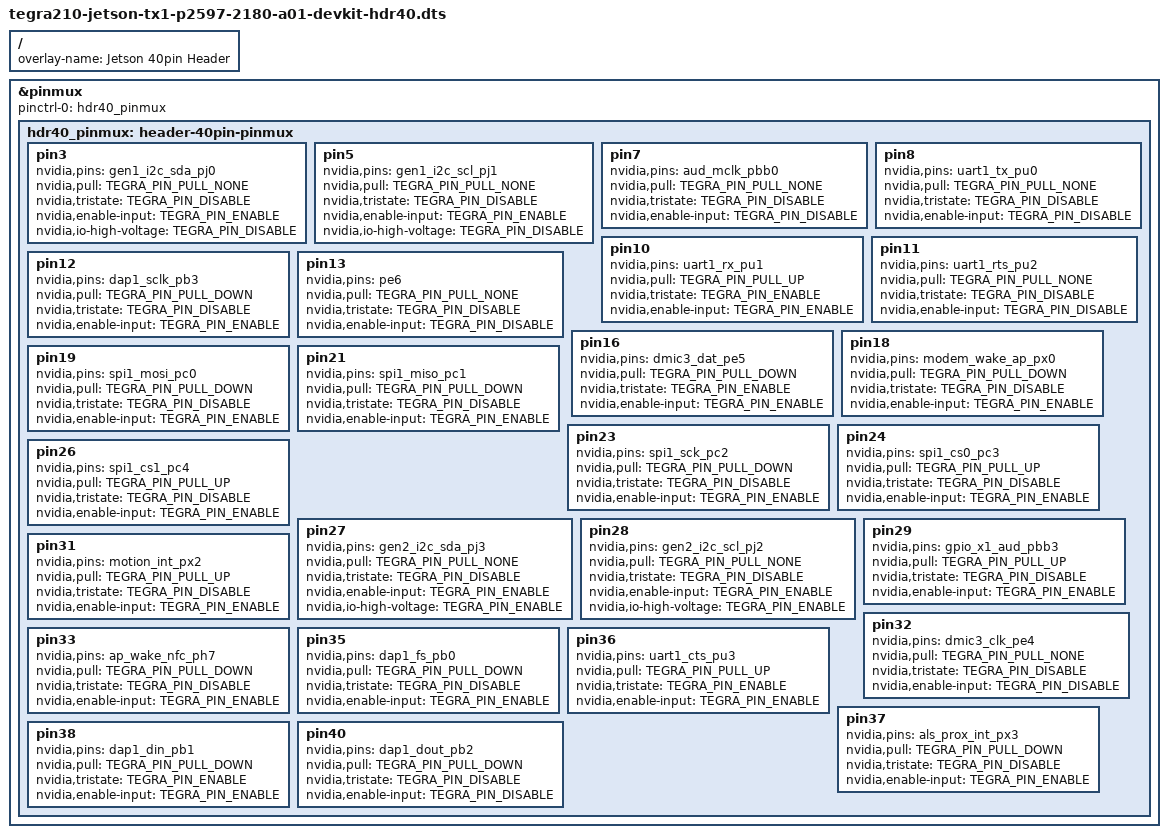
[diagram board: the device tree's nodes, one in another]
// SPDX-License-Identifier: GPL-2.0-only
/*
 * Device-tree overlay for tegra210-jetson-tx1-p2597-2180-a01-devkit
 * 40-pin Expansion Header.
 *
 * Copyright (c) 2019 NVIDIA CORPORATION. All rights reserved.
 *
 */

/dts-v1/;
/plugin/;

#include <dt-bindings/pinctrl/pinctrl-tegra.h>
#include <dt-common/jetson/tegra210-jetson-tx1-p2597-2180-a01-devkit.h>

/ {
	overlay-name = "Jetson 40pin Header";
	compatible = JETSON_COMPATIBLE;

	fragment@0 {
		target = <&pinmux>;
		__overlay__ {
			pinctrl-names = "default";
			pinctrl-0 = <&hdr40_pinmux>;
			hdr40_pinmux: header-40pin-pinmux {
				pin3 {
					nvidia,pins = "gen1_i2c_sda_pj0";
					nvidia,pull = <TEGRA_PIN_PULL_NONE>;
					nvidia,tristate = <TEGRA_PIN_DISABLE>;
					nvidia,enable-input = <TEGRA_PIN_ENABLE>;
					nvidia,io-high-voltage = <TEGRA_PIN_DISABLE>;
				};
				pin5 {
					nvidia,pins = "gen1_i2c_scl_pj1";
					nvidia,pull = <TEGRA_PIN_PULL_NONE>;
					nvidia,tristate = <TEGRA_PIN_DISABLE>;
					nvidia,enable-input = <TEGRA_PIN_ENABLE>;
					nvidia,io-high-voltage = <TEGRA_PIN_DISABLE>;
				};
				pin7 {
					nvidia,pins = "aud_mclk_pbb0";
					nvidia,pull = <TEGRA_PIN_PULL_NONE>;
					nvidia,tristate = <TEGRA_PIN_DISABLE>;
					nvidia,enable-input = <TEGRA_PIN_DISABLE>;
				};
				pin8 {
					nvidia,pins = "uart1_tx_pu0";
					nvidia,pull = <TEGRA_PIN_PULL_NONE>;
					nvidia,tristate = <TEGRA_PIN_DISABLE>;
					nvidia,enable-input = <TEGRA_PIN_DISABLE>;
				};
				pin10 {
					nvidia,pins = "uart1_rx_pu1";
					nvidia,pull = <TEGRA_PIN_PULL_UP>;
					nvidia,tristate = <TEGRA_PIN_ENABLE>;
					nvidia,enable-input = <TEGRA_PIN_ENABLE>;
				};
				pin11 {
					nvidia,pins = "uart1_rts_pu2";
					nvidia,pull = <TEGRA_PIN_PULL_NONE>;
					nvidia,tristate = <TEGRA_PIN_DISABLE>;
					nvidia,enable-input = <TEGRA_PIN_DISABLE>;
				};
				pin12 {
					nvidia,pins = "dap1_sclk_pb3";
					nvidia,pull = <TEGRA_PIN_PULL_DOWN>;
					nvidia,tristate = <TEGRA_PIN_DISABLE>;
					nvidia,enable-input = <TEGRA_PIN_ENABLE>;
				};
				pin13 {
					nvidia,pins = "pe6";
					nvidia,pull = <TEGRA_PIN_PULL_NONE>;
					nvidia,tristate = <TEGRA_PIN_DISABLE>;
					nvidia,enable-input = <TEGRA_PIN_DISABLE>;
				};
				pin16 {
					nvidia,pins = "dmic3_dat_pe5";
					nvidia,pull = <TEGRA_PIN_PULL_DOWN>;
					nvidia,tristate = <TEGRA_PIN_ENABLE>;
					nvidia,enable-input = <TEGRA_PIN_ENABLE>;
				};
				pin18 {
					nvidia,pins = "modem_wake_ap_px0";
					nvidia,pull = <TEGRA_PIN_PULL_DOWN>;
					nvidia,tristate = <TEGRA_PIN_DISABLE>;
					nvidia,enable-input = <TEGRA_PIN_ENABLE>;
				};
				pin19 {
					nvidia,pins = "spi1_mosi_pc0";
					nvidia,pull = <TEGRA_PIN_PULL_DOWN>;
					nvidia,tristate = <TEGRA_PIN_DISABLE>;
					nvidia,enable-input = <TEGRA_PIN_ENABLE>;
				};
				pin21 {
					nvidia,pins = "spi1_miso_pc1";
					nvidia,pull = <TEGRA_PIN_PULL_DOWN>;
					nvidia,tristate = <TEGRA_PIN_DISABLE>;
					nvidia,enable-input = <TEGRA_PIN_ENABLE>;
				};
				pin23 {
					nvidia,pins = "spi1_sck_pc2";
					nvidia,pull = <TEGRA_PIN_PULL_DOWN>;
					nvidia,tristate = <TEGRA_PIN_DISABLE>;
					nvidia,enable-input = <TEGRA_PIN_ENABLE>;
				};
				pin24 {
					nvidia,pins = "spi1_cs0_pc3";
					nvidia,pull = <TEGRA_PIN_PULL_UP>;
					nvidia,tristate = <TEGRA_PIN_DISABLE>;
					nvidia,enable-input = <TEGRA_PIN_ENABLE>;
				};
				pin26 {
					nvidia,pins = "spi1_cs1_pc4";
					nvidia,pull = <TEGRA_PIN_PULL_UP>;
					nvidia,tristate = <TEGRA_PIN_DISABLE>;
					nvidia,enable-input = <TEGRA_PIN_ENABLE>;
				};
				pin27 {
					nvidia,pins = "gen2_i2c_sda_pj3";
					nvidia,pull = <TEGRA_PIN_PULL_NONE>;
					nvidia,tristate = <TEGRA_PIN_DISABLE>;
					nvidia,enable-input = <TEGRA_PIN_ENABLE>;
					nvidia,io-high-voltage = <TEGRA_PIN_ENABLE>;
				};
				pin28 {
					nvidia,pins = "gen2_i2c_scl_pj2";
					nvidia,pull = <TEGRA_PIN_PULL_NONE>;
					nvidia,tristate = <TEGRA_PIN_DISABLE>;
					nvidia,enable-input = <TEGRA_PIN_ENABLE>;
					nvidia,io-high-voltage = <TEGRA_PIN_ENABLE>;
				};
				pin29 {
					nvidia,pins = "gpio_x1_aud_pbb3";
					nvidia,pull = <TEGRA_PIN_PULL_UP>;
					nvidia,tristate = <TEGRA_PIN_DISABLE>;
					nvidia,enable-input = <TEGRA_PIN_ENABLE>;
				};
				pin31 {
					nvidia,pins = "motion_int_px2";
					nvidia,pull = <TEGRA_PIN_PULL_UP>;
					nvidia,tristate = <TEGRA_PIN_DISABLE>;
					nvidia,enable-input = <TEGRA_PIN_ENABLE>;
				};
				pin32 {
					nvidia,pins = "dmic3_clk_pe4";
					nvidia,pull = <TEGRA_PIN_PULL_NONE>;
					nvidia,tristate = <TEGRA_PIN_DISABLE>;
					nvidia,enable-input = <TEGRA_PIN_DISABLE>;
				};
				pin33 {
					nvidia,pins = "ap_wake_nfc_ph7";
					nvidia,pull = <TEGRA_PIN_PULL_DOWN>;
					nvidia,tristate = <TEGRA_PIN_DISABLE>;
					nvidia,enable-input = <TEGRA_PIN_ENABLE>;
				};
				pin35 {
					nvidia,pins = "dap1_fs_pb0";
					nvidia,pull = <TEGRA_PIN_PULL_DOWN>;
					nvidia,tristate = <TEGRA_PIN_DISABLE>;
					nvidia,enable-input = <TEGRA_PIN_ENABLE>;
				};
				pin36 {
					nvidia,pins = "uart1_cts_pu3";
					nvidia,pull = <TEGRA_PIN_PULL_UP>;
					nvidia,tristate = <TEGRA_PIN_ENABLE>;
					nvidia,enable-input = <TEGRA_PIN_ENABLE>;
				};
				pin37 {
					nvidia,pins = "als_prox_int_px3";
					nvidia,pull = <TEGRA_PIN_PULL_DOWN>;
					nvidia,tristate = <TEGRA_PIN_DISABLE>;
					nvidia,enable-input = <TEGRA_PIN_ENABLE>;
				};
				pin38 {
					nvidia,pins = "dap1_din_pb1";
					nvidia,pull = <TEGRA_PIN_PULL_DOWN>;
					nvidia,tristate = <TEGRA_PIN_ENABLE>;
					nvidia,enable-input = <TEGRA_PIN_ENABLE>;
				};
				pin40 {
					nvidia,pins = "dap1_dout_pb2";
					nvidia,pull = <TEGRA_PIN_PULL_DOWN>;
					nvidia,tristate = <TEGRA_PIN_DISABLE>;
					nvidia,enable-input = <TEGRA_PIN_DISABLE>;
				};
			};
		};
	};
};
